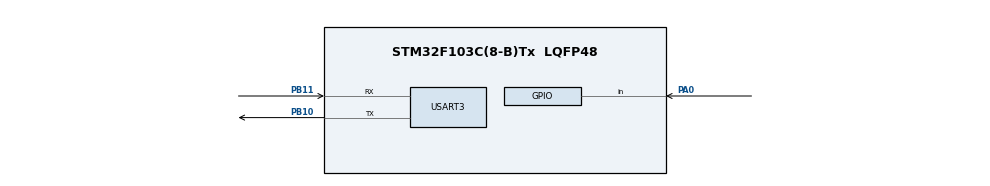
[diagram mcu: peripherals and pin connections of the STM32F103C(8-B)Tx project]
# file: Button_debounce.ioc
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Mcu.Family=STM32F1
Mcu.Name=STM32F103C(8-B)Tx
Mcu.Package=LQFP48
NVIC.PriorityGroup=NVIC_PRIORITYGROUP_4
PA0-WKUP.GPIO_PuPd=GPIO_PULLUP
PA0-WKUP.Signal=GPIO_Input
PA13.Mode=Serial_Wire
PA13.Signal=SYS_JTMS-SWDIO
PA14.Mode=Serial_Wire
PA14.Signal=SYS_JTCK-SWCLK
PB10.Mode=Asynchronous
PB10.Signal=USART3_TX
PB11.Mode=Asynchronous
PB11.Signal=USART3_RX
ProjectManager.HeapSize=0x200
ProjectManager.StackSize=0x400
ProjectManager.TargetToolchain=STM32CubeIDE
RCC.APB1Freq_Value=8000000
RCC.APB2Freq_Value=8000000
USART3.VirtualMode=VM_ASYNC
board=custom

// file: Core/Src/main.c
/* USER CODE BEGIN Header */
/**
  ******************************************************************************
  * @file           : main.c
  * @brief          : Main program body
  ******************************************************************************
  * @attention
  *
  * <h2><center>&copy; Copyright (c) 2020 STMicroelectronics.
  * All rights reserved.</center></h2>
  *
  * This software component is licensed by ST under BSD 3-Clause license,
  * the "License"; You may not use this file except in compliance with the
  * License. You may obtain a copy of the License at:
  *                        opensource.org/licenses/BSD-3-Clause
  *
  ******************************************************************************
  */
/* USER CODE END Header */

#include "main.h"

/* USER CODE BEGIN Includes */
#include "stdio.h"
/* USER CODE END Includes */

UART_HandleTypeDef huart3;

void SystemClock_Config(void);
static void MX_GPIO_Init(void);
static void MX_USART3_UART_Init(void);
/* USER CODE BEGIN PFP */
void BUTTON_DEBOUCE();
/* USER CODE END PFP */

/* USER CODE BEGIN 0 */
uint8_t _b_cnt,_button_press_b1,BUTTON_MAX_DEBOUCE;
/* USER CODE END 0 */

int main(void)
{

  /* MCU Configuration--------------------------------------------------------*/

  /* Reset of all peripherals, Initializes the Flash interface and the Systick. */
  HAL_Init();

  /* Configure the system clock */
  SystemClock_Config();

  /* Initialize all configured peripherals */
  MX_GPIO_Init();
  MX_USART3_UART_Init();

  /* Infinite loop */
  /* USER CODE BEGIN WHILE */
  while (1)
  {
	   uint8_t cnt;
	  if(!HAL_GPIO_ReadPin(GPIOA, GPIO_PIN_0))
	  {
		  while(!HAL_GPIO_ReadPin(GPIOA, GPIO_PIN_0));
		  cnt++;
	  }

	  printf("%d\r\n",cnt);
//	  void BUTTON_DEBOUCE();
//	  printf("%d\r\n",_b_cnt);
//	  if(_button_press_b1 )
//	  {
//		  while(_button_press_b1);
//		  cnt++;
//	  }
	  //printf("%d\r\n",cnt);
	  HAL_Delay(50);
    /* USER CODE END WHILE */

  }
}

void SystemClock_Config(void)
{
  RCC_OscInitTypeDef RCC_OscInitStruct = {0};
  RCC_ClkInitTypeDef RCC_ClkInitStruct = {0};

  /** Initializes the CPU, AHB and APB busses clocks
  */
  RCC_OscInitStruct.OscillatorType = RCC_OSCILLATORTYPE_HSI;
  RCC_OscInitStruct.HSIState = RCC_HSI_ON;
  RCC_OscInitStruct.HSICalibrationValue = RCC_HSICALIBRATION_DEFAULT;
  RCC_OscInitStruct.PLL.PLLState = RCC_PLL_NONE;
  if (HAL_RCC_OscConfig(&RCC_OscInitStruct) != HAL_OK)
  {
    Error_Handler();
  }
  /** Initializes the CPU, AHB and APB busses clocks
  */
  RCC_ClkInitStruct.ClockType = RCC_CLOCKTYPE_HCLK|RCC_CLOCKTYPE_SYSCLK
                              |RCC_CLOCKTYPE_PCLK1|RCC_CLOCKTYPE_PCLK2;
  RCC_ClkInitStruct.SYSCLKSource = RCC_SYSCLKSOURCE_HSI;
  RCC_ClkInitStruct.AHBCLKDivider = RCC_SYSCLK_DIV1;
  RCC_ClkInitStruct.APB1CLKDivider = RCC_HCLK_DIV1;
  RCC_ClkInitStruct.APB2CLKDivider = RCC_HCLK_DIV1;

  if (HAL_RCC_ClockConfig(&RCC_ClkInitStruct, FLASH_LATENCY_0) != HAL_OK)
  {
    Error_Handler();
  }
}

static void MX_USART3_UART_Init(void)
{

  huart3.Instance = USART3;
  huart3.Init.BaudRate = 115200;
  huart3.Init.WordLength = UART_WORDLENGTH_8B;
  huart3.Init.StopBits = UART_STOPBITS_1;
  huart3.Init.Parity = UART_PARITY_NONE;
  huart3.Init.Mode = UART_MODE_TX_RX;
  huart3.Init.HwFlowCtl = UART_HWCONTROL_NONE;
  huart3.Init.OverSampling = UART_OVERSAMPLING_16;
  if (HAL_UART_Init(&huart3) != HAL_OK)
  {
    Error_Handler();
  }

}

static void MX_GPIO_Init(void)
{
  GPIO_InitTypeDef GPIO_InitStruct = {0};

  /* GPIO Ports Clock Enable */
  __HAL_RCC_GPIOA_CLK_ENABLE();
  __HAL_RCC_GPIOB_CLK_ENABLE();

  /*Configure GPIO pin : PA0 */
  GPIO_InitStruct.Pin = GPIO_PIN_0;
  GPIO_InitStruct.Mode = GPIO_MODE_INPUT;
  GPIO_InitStruct.Pull = GPIO_PULLUP;
  HAL_GPIO_Init(GPIOA, &GPIO_InitStruct);

}

/* USER CODE BEGIN 4 */

void BUTTON_DEBOUCE()
{

		if (!HAL_GPIO_ReadPin(GPIOA, GPIO_PIN_0)) {
			_b_cnt++;
			if (_b_cnt > (128 + BUTTON_MAX_DEBOUCE)){
				_b_cnt = (128 + BUTTON_MAX_DEBOUCE);
				_button_press_b1 = 1;
			}
		}
		else {
			_b_cnt--;
			if (_b_cnt < (128 - BUTTON_MAX_DEBOUCE)){
				_b_cnt = (128 - BUTTON_MAX_DEBOUCE);
				_button_press_b1 = 0;
			}
		}

  return _button_press_b1;
}

#ifdef __GNUC__
#define PUTCHAR_PROTOTYPE int __io_putchar(int ch)
#else
#define PUTCHAR_PROTOTYPE int fputc(int ch, FILE *f)
#endif /* __GNUC__ */

PUTCHAR_PROTOTYPE
{
HAL_UART_Transmit(&huart3, (uint8_t *)&ch, 1, 100);
return ch;
}
/* USER CODE END 4 */

void Error_Handler(void)
{
}

/************************ (C) COPYRIGHT STMicroelectronics *****END OF FILE****/
